# CY8C5267AXI_LP051 register map
File version: 0.1
CY8C52LP
Registers are 8-bit, read-write, no defined reset value unless marked. A register's access mark holds for its fields unless they carry their own. Offsets are from the block's base; lines under a group give offsets from that group; [hi:lo] are bit positions; {n}, {i} and the like mark numbered series; 'fields as' and 'values as' point back to an identical list; <NAME> marks a mode.

## Memory map
0x00000000 SPI_ADDR
0x00000000 I2C1
0x00000000 USBUART — USBFS
0x00000000 I2C_EEPROM

## SPI_ADDR
Base 0x00000000
0x4000647A SPI_ADDR_CONTROL_REG

## I2C1
Base 0x00000000
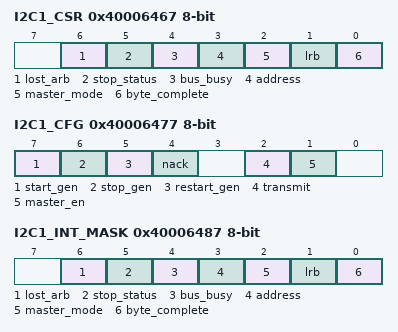
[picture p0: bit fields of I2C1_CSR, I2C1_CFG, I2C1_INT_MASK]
0x40006467 I2C1_CSR — I2C Status Register
  [6] lost_arb ro — If set, indicates arbitration was lost (multi-master and multi-master-slave modes).
  [5] stop_status ro — If set, indicates a Stop condition was detected on the bus.
  [4] bus_busy ro — If set, indicates the bus is busy. Data is currently being transmitted or received.
  [3] address ro — Address detection. If set, indicates that an address byte was sent.
  [2] master_mode ro — Indicates that a valid Start condition was generated and a hardware device is operating as bus master.
  [1] lrb ro — Last Received Bit. Indicates the state of the last received bit, which is the ACK/NAK received for the last byte transmitted. Cleared = ACK and set = NAK.
  [0] byte_complete ro — Transmit or receive status since the last read of this register. In Transmit mode this bit indicates that eight bits of data plus ACK/NAK have been transmitted since the last read. In Receive mode this bit indicates that eight bits of data have been received since the last read of this register.
0x40006477 I2C1_CFG — I2C Configuration Register
  [7] start_gen — Set to 1 to generate a Start condition on the bus. This bit must be cleared by firmware before initiating the next transaction.
  [6] stop_gen — Set to 1 to generate a Stop condition on the bus. This bit must be cleared by firmware before initiating the next transaction.
  [5] restart_gen — Set to 1 to generate a Restart condition on the bus. This bit must be cleared by firmware after a Restart condition is generated.
  [4] nack — Set to 1 to NAK the next read byte. Clear to ACK next read byte. This bit must be cleared by firmware between bytes.
  [2] transmit — Set to 1 to set the current mode to transmit or clear to 0 to receive a byte of data. This bit must be cleared by firmware before starting the next transmit or receive transaction.
  [1] master_en — Set to 1 to enable the master functionality.
0x40006487 I2C1_INT_MASK — I2C Interrupt Enable Mask
  [6] lost_arb — Enables interrupt from the corresponding bit in status register.
  [5] stop_status — Enables interrupt from the corresponding bit in status register.
  [4] bus_busy — Enables interrupt from the corresponding bit in status register.
  [3] address — Enables interrupt from the corresponding bit in status register.
  [2] master_mode — Enables interrupt from the corresponding bit in status register.
  [1] lrb — Enables interrupt from the corresponding bit in status register.
  [0] byte_complete — Enables interrupt from the corresponding bit in status register.
0x40006505 I2C1_DATA — I2C Data Register
  [7:0] data — Read received data or write data to transmit.
